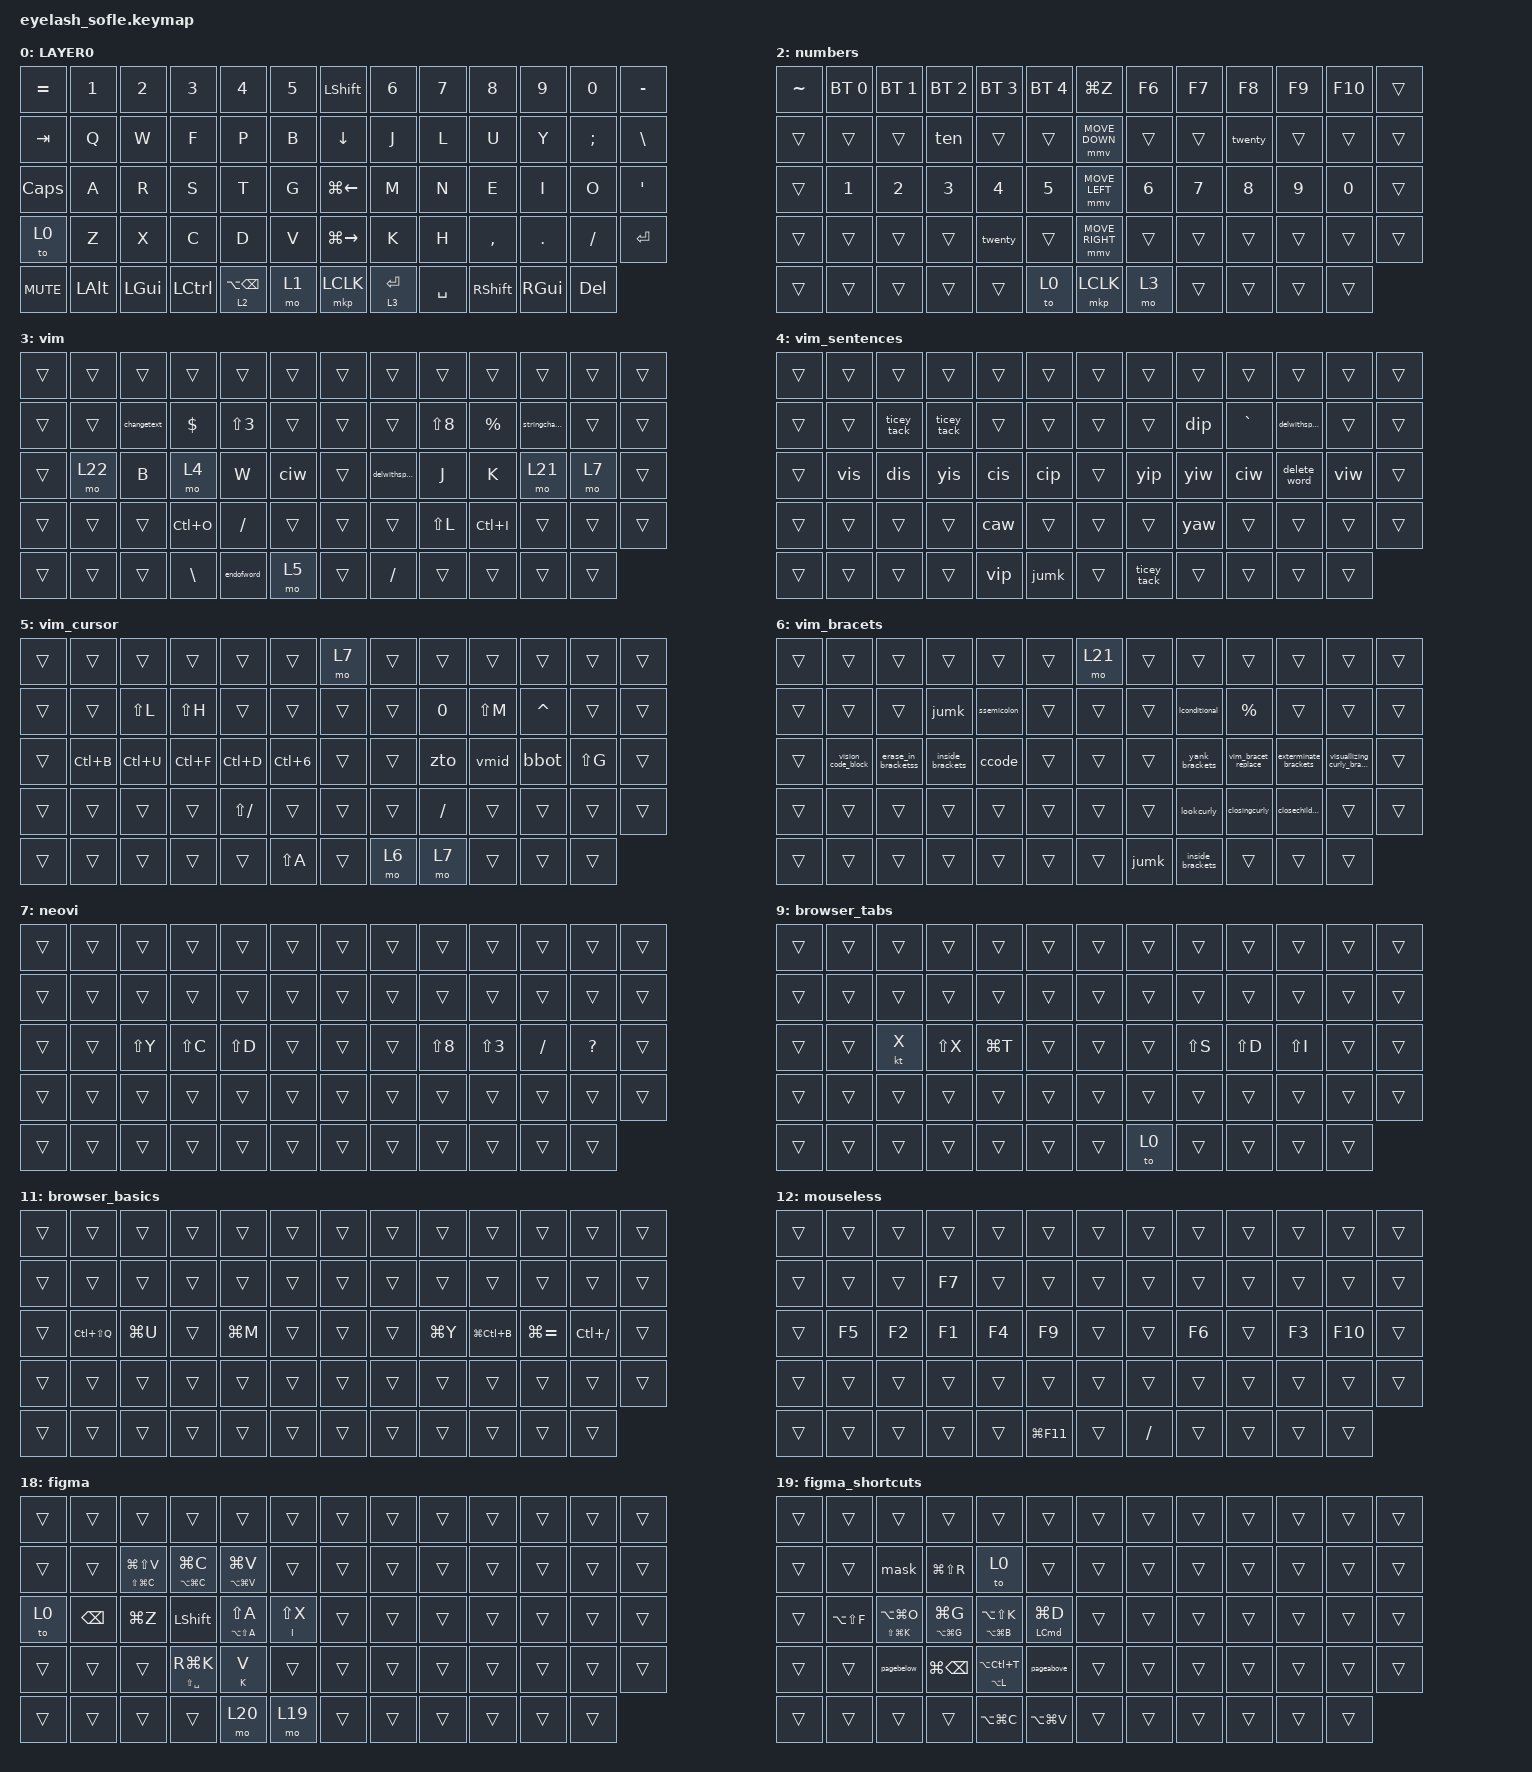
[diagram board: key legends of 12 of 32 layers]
#define ZMK_POINTING_DEFAULT_MOVE_VAL 1200  // 600
#define ZMK_POINTING_DEFAULT_SCRL_VAL 25   // 10

#include <input/processors.dtsi>
#include <zephyr/dt-bindings/input/input-event-codes.h>
#include <behaviors.dtsi>
#include <dt-bindings/zmk/bt.h>
#include <dt-bindings/zmk/keys.h>
#include <dt-bindings/zmk/pointing.h>

&mmv_input_listener { input-processors = <&zip_xy_scaler 2 1>; };

&msc_input_listener { input-processors = <&zip_scroll_scaler 2 1>; };

&msc {
    acceleration-exponent = <1>;      // 0
    time-to-max-speed-ms = <100>;       // 300
    delay-ms = <0>;                   // 0
};

&mmv {
    time-to-max-speed-ms = <500>;
    acceleration-exponent = <1>;
    trigger-period-ms = <16>;
};

/ {
    scroll_encoder: scroll_encoder {
        compatible = "zmk,behavior-sensor-rotate";
        #sensor-binding-cells = <0>;
        bindings = <&msc SCRL_DOWN>, <&msc SCRL_UP>;

        tap-ms = <100>;
    };

    new_behavior: new_behavior {
        compatible = "zmk,behavior-hold-tap";
        label = "NEW_BEHAVIOR";
        bindings = <&mo>, <&kp>;

        #binding-cells = <2>;
        tapping-term-ms = <200>;
        quick-tap-ms = <165>;
        flavor = "tap-preferred";
        hold-trigger-on-release;
    };

    new_behaviorr: new_behaviorr {
        compatible = "zmk,behavior-hold-tap";
        label = "NEW_BEHAVIORR";
        bindings = <&mo>, <&to>;

        #binding-cells = <2>;
        tapping-term-ms = <200>;
        quick-tap-ms = <150>;
        hold-trigger-on-release;
    };

    behaviors {
    };

    combos {
        compatible = "zmk,combos";

        deleteword {
            bindings = <&ciw>;
            key-positions = <30 34>;
        };

        top {
            bindings = <&kp LA(LS(N))>;
            key-positions = <28 29>;
        };

        vimjumps {
            bindings = <&jumk>;
            key-positions = <23 34>;
        };

        searh {
            bindings = <&kp SLASH>;
            key-positions = <27 37>;
        };

        fspace {
            bindings = <&gospace>;
            key-positions = <30 16>;
        };
    };

    macros {
        ciw: ciw {
            compatible = "zmk,behavior-macro";
            #binding-cells = <0>;
            bindings = <&kp C &kp I &kp W>;
            label = "ciw";
        };

        viw: viw {
            compatible = "zmk,behavior-macro";
            #binding-cells = <0>;
            bindings = <&kp V &kp I &kp W>;
            label = "VIW";
        };

        yiw: yiw {
            compatible = "zmk,behavior-macro";
            #binding-cells = <0>;
            bindings = <&kp Y &kp I &kp W>;
            label = "YIW";
        };

        ten: ten {
            compatible = "zmk,behavior-macro";
            #binding-cells = <0>;
            bindings = <&kp NUMBER_1 &kp N0>;
            label = "ten";
        };

        delete_word: delete_word {
            compatible = "zmk,behavior-macro";
            #binding-cells = <0>;
            bindings = <&kp D &kp I &kp W>;
            label = "DELETE_WORD";
        };

        replace_word: replace_word {
            compatible = "zmk,behavior-macro";
            #binding-cells = <0>;
            bindings = <&kp C &kp I &kp LS(W)>;
            label = "REPLACE_WORD";
        };

        visual_w: visual_w {
            compatible = "zmk,behavior-macro";
            #binding-cells = <0>;
            bindings = <&kp V &kp I &kp LS(W)>;
            label = "VISUAL_W";
        };

        copy_word: copy_word {
            compatible = "zmk,behavior-macro";
            #binding-cells = <0>;
            bindings = <&kp Y &kp I &kp LS(W)>;
            label = "COPY_WORD";
        };

        remove_o: remove_o {
            compatible = "zmk,behavior-macro";
            #binding-cells = <0>;
            bindings = <&kp D &kp I &kp LS(W)>;
            label = "REMOVE_O";
        };

        twenty: twenty {
            compatible = "zmk,behavior-macro";
            #binding-cells = <0>;
            bindings = <&kp NUMBER_2 &kp N0>;
            label = "TWENTY";
        };

        vim_bracet_replace: vim_bracet_replace {
            compatible = "zmk,behavior-macro";
            #binding-cells = <0>;
            bindings = <&kp C &kp I &kp B>;
            label = "VIM_BRACET_REPLACE";
        };

        inside_brackets: replace_inside_brackets {
            compatible = "zmk,behavior-macro";
            #binding-cells = <0>;
            bindings = <&kp C &kp I &kp LS(B)>;
            label = "REPLACE_INSIDE_BRACKETS";
        };

        ccode: copy_code {
            compatible = "zmk,behavior-macro";
            #binding-cells = <0>;
            bindings = <&kp Y &kp I &kp B>;
            label = "COPY_CODE";
        };

        yank_brackets: yank_brackets {
            compatible = "zmk,behavior-macro";
            #binding-cells = <0>;
            bindings = <&kp Y &kp I &kp LS(B)>;
            label = "YANK_BRACKETS";
        };

        erase_in_bracketss: erase_in_bracketss {
            compatible = "zmk,behavior-macro";
            #binding-cells = <0>;
            bindings = <&kp D &kp I &kp B>;
            label = "ERASE_IN_BRACKETSS";
        };

        exterminate_brackets: exterminate_brackets {
            compatible = "zmk,behavior-macro";
            #binding-cells = <0>;
            bindings = <&kp D &kp I &kp LS(B)>;
            label = "EXTERMINATE_BRACKETS";
        };

        vision_code_block: vision_code_block {
            compatible = "zmk,behavior-macro";
            #binding-cells = <0>;
            bindings = <&kp V &kp I &kp B>;
            label = "VISION_CODE_BLOCK";
        };

        visuallizing_curly_brackets: visuallizing_curly_brackets {
            compatible = "zmk,behavior-macro";
            #binding-cells = <0>;
            bindings = <&kp V &kp I &kp LS(B)>;
            label = "VISUALLIZING_CURLY_BRACKETS";
        };

        ticey_tack: ticey_tack {
            compatible = "zmk,behavior-macro";
            #binding-cells = <0>;
            bindings = <&kp GRAVE &kp GRAVE>;
            label = "TICEY_TACK";
        };

        zto: zt {
            compatible = "zmk,behavior-macro";
            #binding-cells = <0>;
            bindings = <&kp Z &kp T>;
            label = "ZT";
        };

        vmid: middle {
            compatible = "zmk,behavior-macro";
            #binding-cells = <0>;
            bindings = <&kp Z &kp Z>;
            label = "MIDDLE";
        };

        bbot: bottom {
            compatible = "zmk,behavior-macro";
            #binding-cells = <0>;
            bindings = <&kp Z &kp B>;
            label = "BOTTOM";
        };

        cip: cip {
            compatible = "zmk,behavior-macro";
            #binding-cells = <0>;
            bindings = <&kp C &kp I &kp P>;
            label = "CIP";
        };

        vip: vip {
            compatible = "zmk,behavior-macro";
            #binding-cells = <0>;
            bindings = <&kp V &kp I &kp P>;
            label = "VIP";
        };

        yip: yip {
            compatible = "zmk,behavior-macro";
            #binding-cells = <0>;
            bindings = <&kp Y &kp I &kp P>;
            label = "YIP";
        };

        dip: dip {
            compatible = "zmk,behavior-macro";
            #binding-cells = <0>;
            bindings = <&kp D &kp I &kp P>;
            label = "DIP";
        };

        cis: cis {
            compatible = "zmk,behavior-macro";
            #binding-cells = <0>;
            bindings = <&kp C &kp I &kp S>;
            label = "CIS";
        };

        vis: vis {
            compatible = "zmk,behavior-macro";
            #binding-cells = <0>;
            bindings = <&kp V &kp I &kp S>;
            label = "VIS";
        };

        yis: yis {
            compatible = "zmk,behavior-macro";
            #binding-cells = <0>;
            bindings = <&kp Y &kp I &kp S>;
            label = "YIS";
        };

        dis: dis {
            compatible = "zmk,behavior-macro";
            #binding-cells = <0>;
            bindings = <&kp D &kp I &kp S>;
            label = "DIS";
        };

        caw: caw {
            compatible = "zmk,behavior-macro";
            #binding-cells = <0>;
            bindings = <&kp C &kp A &kp W>;
            label = "CAW";
        };

        yaw: yaw {
            compatible = "zmk,behavior-macro";
            #binding-cells = <0>;
            bindings = <&kp Y &kp A &kp W>;
            label = "YAW";
        };

        endofword: endofword {
            compatible = "zmk,behavior-macro";
            #binding-cells = <0>;
            bindings = <&kp G &kp E>;
            label = "ENDOFWORD";
        };

        jumk: jumpy {
            compatible = "zmk,behavior-macro";
            #binding-cells = <0>;
            bindings = <&kp GRAVE &kp N>;
            label = "JUMPY";
        };

        splitV: splitV {
            compatible = "zmk,behavior-macro";
            #binding-cells = <0>;
            bindings = <&kp SPACE &kp S &kp V>;
            label = "SPLITV";
        };

        horsplit: horsplit {
            compatible = "zmk,behavior-macro";
            #binding-cells = <0>;
            bindings = <&kp SPACE &kp S &kp H>;
            label = "HORSPLIT";
        };

        closesplit: closesplit {
            compatible = "zmk,behavior-macro";
            #binding-cells = <0>;
            bindings = <&kp SPACE &kp S &kp X>;
            label = "CLOSESPLIT";
        };

        changetext: change_text {
            compatible = "zmk,behavior-macro";
            #binding-cells = <0>;
            bindings = <&kp C &kp I &kp DOUBLE_QUOTES>;
            label = "CHANGE_TEXT";
        };

        stringchange: string_change {
            compatible = "zmk,behavior-macro";
            #binding-cells = <0>;
            bindings = <&kp C &kp I &kp SINGLE_QUOTE>;
            label = "STRING_CHANGE";
        };

        fuzzy: fuzzy {
            compatible = "zmk,behavior-macro";
            #binding-cells = <0>;
            bindings = <&kp F &kp Z &kp F>;
            label = "FUZZY";
        };

        aroundpara: around_para {
            compatible = "zmk,behavior-macro";
            #binding-cells = <0>;
            bindings = <&kp D &kp A &kp P>;
            label = "AROUND_PARA";
        };

        gospace: next_space {
            compatible = "zmk,behavior-macro";
            #binding-cells = <0>;
            bindings = <&kp F &kp SPACE>;
            label = "NEXT_SPACE";
        };

        findbra: findbra {
            compatible = "zmk,behavior-macro";
            #binding-cells = <0>;
            bindings = <&kp F &kp LS(N9)>;
            label = "FINDBRA";
        };

        lookcurly: lookcurly {
            compatible = "zmk,behavior-macro";
            #binding-cells = <0>;
            bindings = <&kp F &kp LEFT_BRACE>;
            label = "LOOKCURLY";
        };

        ssemicolon: ssemicolon {
            compatible = "zmk,behavior-macro";
            #binding-cells = <0>;
            bindings = <&kp F &kp SEMICOLON>;
            label = "SSEMICOLON";
        };

        closingcurly: closingcurly {
            compatible = "zmk,behavior-macro";
            #binding-cells = <0>;
            bindings = <&kp F &kp LS(N0)>;
            label = "CLOSINGCURLY";
        };

        lockedbra: lockedbra {
            compatible = "zmk,behavior-macro";
            #binding-cells = <0>;
            bindings = <&kp F &kp RIGHT_BRACE>;
            label = "LOCKEDBRA";
        };

        seechildren: seechildren {
            compatible = "zmk,behavior-macro";
            #binding-cells = <0>;
            bindings = <&kp F &kp LEFT_BRACKET>;
            label = "SEECHILDREN";
        };

        closechildren: closechildren {
            compatible = "zmk,behavior-macro";
            #binding-cells = <0>;
            bindings = <&kp F &kp RIGHT_BRACKET>;
            label = "CLOSECHILDREN";
        };

        lconditional: lconditional {
            compatible = "zmk,behavior-macro";
            #binding-cells = <0>;
            bindings = <&kp F &kp LS(SEMICOLON)>;
            label = "LCONDITIONAL";
        };

        mask: mask {
            compatible = "zmk,behavior-macro";
            #binding-cells = <0>;
            bindings = <&kp CARET &kp LG(M)>;
            label = "MASK";
        };

        Component: Component {
            compatible = "zmk,behavior-macro";
            #binding-cells = <0>;
            bindings = <&kp CARET &kp LA(LG(K))>;
            label = "COMPONENT";
        };

        pagebelow: pagebelow {
            compatible = "zmk,behavior-macro";
            #binding-cells = <0>;
            bindings = <&kp GLOBE &kp DOWN_ARROW>;
            label = "PAGEBELOW";
        };

        pageabove: pageabove {
            compatible = "zmk,behavior-macro";
            #binding-cells = <0>;
            bindings = <&kp GLOBE &kp UP_ARROW>;
            label = "PAGEABOVE";
        };

        mipassword: mipassword {
            compatible = "zmk,behavior-macro";
            #binding-cells = <0>;
            bindings = <&kp M &kp I &kp G &kp B &kp Y &kp T &kp E &kp DLLR &kp PERCENT>;
            label = "MIPASSWORD";
        };

        muxprev: muxprev {
            compatible = "zmk,behavior-macro";
            #binding-cells = <0>;
            bindings = <&kp LC(N) &kp LC(P)>;
            label = "MUXPREV";
        };

        delwithspacedaw: delwithspacedaw {
            compatible = "zmk,behavior-macro";
            #binding-cells = <0>;
            bindings = <&kt D &kp W>;
            label = "DELWITHSPACEDAW";
        };

        winsert: winsert {
            compatible = "zmk,behavior-macro";
            #binding-cells = <0>;
            bindings = <&kp LC(O) &kp W>;
            label = "WINSERT";
        };

        begininsertmode: begininsertmode {
            compatible = "zmk,behavior-macro";
            #binding-cells = <0>;
            bindings = <&kp LC(O) &kp B>;
            label = "BEGININSERTMODE";
        };

        endinertm: doinertm {
            compatible = "zmk,behavior-macro";
            #binding-cells = <0>;
            bindings = <&kp LC(O) &kp RIGHT_ARROW &kp E>;
            label = "DOINERTM";
        };

        var: var {
            compatible = "zmk,behavior-macro";
            #binding-cells = <0>;
            bindings = <&kp DOLLAR &kp V &kp A &kp R>;
            label = "VAR";
        };

        eloquentchain: eloquentchain {
            compatible = "zmk,behavior-macro";
            #binding-cells = <0>;
            bindings = <&kp MINUS &kp GREATER_THAN>;
            label = "ELOQUENTCHAIN";
        };

        phpopening: phpopening {
            compatible = "zmk,behavior-macro";
            #binding-cells = <0>;
            bindings = <&kp LESS_THAN &kp QUESTION &kp P &kp H &kp P &kp QUESTION &kp GREATER_THAN>;
            label = "PHPOPENING";
        };

        array: array {
            compatible = "zmk,behavior-macro";
            #binding-cells = <0>;
            bindings = <&kp EQUAL &kp GREATER_THAN>;
            label = "ARRAY";
        };

        passdata: passdata {
            compatible = "zmk,behavior-macro";
            #binding-cells = <0>;
            bindings = <&none &kp C &kp O &kp M &kp P &kp A &kp C &kp T &kp LPAR &kp SQT &kp V &kp A &kp R &kp SQT &kp RPAR>;
            label = "PASSDATA";
        };

        pssword: pssword {
            compatible = "zmk,behavior-macro";
            #binding-cells = <0>;
            bindings = <&none &kp LS(M) &kp I &kp G &kp B &kp Y &kp T &kp E &kp N1 &kp N9 &kp N9 &kp N6 &kp DLLR>;
            label = "PSSWORD";
        };

        lasteditlo: lasteditlo {
            compatible = "zmk,behavior-macro";
            #binding-cells = <0>;
            bindings = <&kp SINGLE_QUOTE &kp PERIOD>;
            label = "LASTEDITLO";
        };

        lastinertlo: lastinertlo {
            compatible = "zmk,behavior-macro";
            #binding-cells = <0>;
            bindings = <&kp SINGLE_QUOTE &kp CARET>;
            label = "LASTINERTLO";
        };

        lastvimchange: lastvimchange {
            compatible = "zmk,behavior-macro";
            #binding-cells = <0>;
            bindings = <&kp SINGLE_QUOTE &kp LEFT_BRACKET>;
            label = "LASTVIMCHANGE";
        };

        firstvimchange: firstvimchange {
            compatible = "zmk,behavior-macro";
            #binding-cells = <0>;
            bindings = <&kp SQT &kp RIGHT_BRACKET>;
            label = "FIRSTVIMCHANGE";
        };

        entireprojectwordreplace: entireprojectwordreplace {
            compatible = "zmk,behavior-macro";
            #binding-cells = <0>;
            bindings = <&kp COLON &kp C &kp D &kp O &kp SPACE &kp S &kp SLASH>;
            label = "ENTIREPROJECTWORDREPLACE";
        };

        searchpopluateqfixdart: searchpopluateqfix {
            compatible = "zmk,behavior-macro";
            #binding-cells = <0>;
            bindings = <&kp COLON &kp V &kp I &kp M &kp SPACE &kp SLASH &kp BACKSLASH &kp LESS_THAN &kp BACKSLASH &kp GREATER_THAN &kp SLASH &kp G &kp J &kp SPACE &kp ASTERISK &kp ASTERISK &kp SLASH &kp ASTRK &kp PERIOD &kp D &kp A &kp R &kp T &kp LEFT_ARROW &kp LEFT_ARROW &kp LEFT_ARROW &kp LEFT_ARROW &kp LEFT_ARROW &kp LEFT_ARROW &kp LEFT_ARROW &kp LEFT_ARROW &kp LEFT_ARROW &kp LEFT_ARROW &kp LEFT_ARROW &kp LEFT_ARROW &kp LEFT_ARROW &kp LEFT_ARROW &kp LEFT_ARROW>;
            label = "SEARCHPOPLUATEQFIX";
        };

        nexterror: newerror {
            compatible = "zmk,behavior-macro";
            #binding-cells = <0>;
            bindings = <&kp RIGHT_BRACKET &kp E>;
            label = "NEWERROR";
        };

        nextdiagnostic: newdiagnostic {
            compatible = "zmk,behavior-macro";
            #binding-cells = <0>;
            bindings = <&kp RIGHT_BRACKET &kp D>;
            label = "NEWDIAGNOSTIC";
        };

        previousdiagnostic: previousdiagnostic {
            compatible = "zmk,behavior-macro";
            #binding-cells = <0>;
            bindings = <&kp LEFT_BRACKET &kp D>;
            label = "PREVIOUSDIAGNOSTIC";
        };

        previouserror: previouserror {
            compatible = "zmk,behavior-macro";
            #binding-cells = <0>;
            bindings = <&kp LEFT_BRACKET &kp E>;
            label = "PREVIOUSERROR";
        };

        flutterentirewordreplace: flutterentirewordreplace {
            compatible = "zmk,behavior-macro";
            #binding-cells = <0>;
            bindings = <&kp COLON &kp C &kp F &kp D &kp O &kp SPACE &kp PRCNT &kp S &kp FSLH &kp FSLH &kp FSLH &kp G &kp SPACE &kp PIPE &kp SPACE &kp U &kp P &kp D &kp A &kp T &kp E &kp LEFT_ARROW &kp LEFT_ARROW &kp LEFT_ARROW &kp LEFT_ARROW &kp LEFT_ARROW &kp LEFT_ARROW &kp LEFT_ARROW &kp LEFT_ARROW &kp LEFT_ARROW &kp LEFT_ARROW &kp LEFT_ARROW>;
            label = "FLUTTERENTIREWORDREPLACE";
        };

        justreplace: justreplace {
            compatible = "zmk,behavior-macro";
            #binding-cells = <0>;
            bindings = <&kp COLON &kp PRCNT &kp S &kp FSLH &kp FSLH &kp FSLH &kp LEFT_ARROW &kp LEFT_ARROW>;
            label = "JUSTREPLACE";
        };
    };

    keymap {
        compatible = "zmk,keymap";

        kuru {
            bindings = <
&kp EQUAL   &kp N1        &kp N2        &kp N3            &kp N4                         &kp N5    &kp LEFT_SHIFT       &kp N6               &kp N7     &kp N8           &kp N9         &kp N0         &kp MINUS
&kp TAB     &kp Q         &kp W         &kp F             &kp P                          &kp B     &kp DOWN_ARROW       &kp J                &kp L      &kp U            &kp Y          &kp SEMICOLON  &kp BSLH
&kp CAPS    &kp A         &kp R         &kp S             &kp T                          &kp G     &kp LG(LEFT_ARROW)   &kp M                &kp N      &kp E            &kp I          &kp O          &kp APOS
&to 0       &kp Z         &kp X         &kp C             &kp D                          &kp V     &kp LG(RIGHT_ARROW)  &kp K                &kp H      &kp COMMA        &kp DOT        &kp FSLH       &kp ENTER
&kp C_MUTE  &kp LEFT_ALT  &kp LEFT_GUI  &kp LEFT_CONTROL  &new_behavior 2 LA(BACKSPACE)  &mo 1     &mkp LCLK            &new_behavior 3 RET  &kp SPACE  &kp RIGHT_SHIFT  &kp RIGHT_GUI  &kp DELETE
            >;

            sensor-bindings = <&inc_dec_kp C_VOLUME_UP C_VOL_DN>;
            display-name = "LAYER0";
        };

        all {
            bindings = <
&sys_reset    &bt BT_CLR_ALL  &bt BT_CLR  &bt BT_NXT  &bt BT_PRV  &bt BT_SEL 4    &kp LG(BACKSPACE)  &kp F6             &kp F7                 &kp F8         &kp F9            &kp F10  &sys_reset
&bt BT_SEL 1  &none           &kp LG(Y)   &kp LG(W)   &to 18      &trans          &mmv MOVE_DOWN     &kp DOUBLE_QUOTES  &kp LC(LA(LG(SLASH)))  &mo 8          &kp SINGLE_QUOTE  &trans   &trans
&sys_reset    &mo 23          &mo 26      &mo 6       &mo 13      &kp F8          &mmv MOVE_LEFT     &kp LC(LA(LG(F)))  &kp TAB                &kp LC(W)      &kp ESCAPE        &mo 30   &kp Z
&bt BT_SEL 0  &trans          &kp LG(X)   &kp LG(C)   &kp LG(V)   &trans          &mmv MOVE_RIGHT    &trans             &findbra               &closingcurly  &seechildren      &trans   &pssword
&trans        &trans          &trans      &trans      &trans      &trans          &mkp LCLK          &kp LC(S)          &mo 17                 &kp LG(Z)      &mipassword       &trans
            >;

            display-name = "layer1";
            sensor-bindings = <&scroll_encoder>;
        };

        numbers {
            bindings = <
&kp TILDE  &bt BT_SEL 0  &bt BT_SEL 1  &bt BT_SEL 2  &bt BT_SEL 3  &bt BT_SEL 4    &kp LG(Z)        &kp F6        &kp F7  &kp F8   &kp F9  &kp F10  &trans
&trans     &trans        &trans        &ten          &trans        &trans          &mmv MOVE_DOWN   &trans        &trans  &twenty  &trans  &trans   &trans
&trans     &kp NUMBER_1  &kp NUMBER_2  &kp NUMBER_3  &kp NUMBER_4  &kp N5          &mmv MOVE_LEFT   &kp NUMBER_6  &kp N7  &kp N8   &kp N9  &kp N0   &trans
&trans     &trans        &trans        &trans        &twenty       &trans          &mmv MOVE_RIGHT  &trans        &trans  &trans   &trans  &trans   &trans
&trans     &trans        &trans        &trans        &trans        &to 0           &mkp LCLK        &mo 3         &trans  &trans   &trans  &trans
            >;

            sensor-bindings = <&scroll_encoder>;
        };

        vim {
            bindings = <
&trans  &trans  &trans       &trans         &trans            &trans    &trans  &trans            &trans      &trans       &trans         &trans  &trans
&trans  &trans  &changetext  &kp DOLLAR     &kp LS(NUMBER_3)  &trans    &trans  &trans            &kp LS(N8)  &kp PERCENT  &stringchange  &trans  &trans
&trans  &mo 22  &kp B        &mo 4          &kp W             &ciw      &trans  &delwithspacedaw  &kp J       &kp K        &mo 21         &mo 7   &trans
&trans  &trans  &trans       &kp LC(O)      &kp SLASH         &trans    &trans  &trans            &kp LS(L)   &kp LC(I)    &trans         &trans  &trans
&trans  &trans  &trans       &kp BACKSLASH  &endofword        &mo 5     &trans  &kp SLASH         &trans      &trans       &trans         &trans
            >;

            sensor-bindings = <&inc_dec_kp PLUS KP_SUBTRACT>;
        };

        vim_sentences {
            bindings = <
&trans  &trans  &trans       &trans       &trans  &trans    &trans  &trans       &trans  &trans     &trans            &trans  &trans
&trans  &trans  &ticey_tack  &ticey_tack  &trans  &trans    &trans  &trans       &dip    &kp GRAVE  &delwithspacedaw  &trans  &trans
&trans  &vis    &dis         &yis         &cis    &cip      &trans  &yip         &yiw    &ciw       &delete_word      &viw    &trans
&trans  &trans  &trans       &trans       &caw    &trans    &trans  &trans       &yaw    &trans     &trans            &trans  &trans
&trans  &trans  &trans       &trans       &vip    &jumk     &trans  &ticey_tack  &trans  &trans     &trans            &trans
            >;
        };

        vim_cursor {
            bindings = <
&trans  &trans     &trans     &trans     &trans         &trans              &mo 7   &trans  &trans     &trans     &trans     &trans     &trans
&trans  &trans     &kp LS(L)  &kp LS(H)  &trans         &trans              &trans  &trans  &kp N0     &kp LS(M)  &kp CARET  &trans     &trans
&trans  &kp LC(B)  &kp LC(U)  &kp LC(F)  &kp LC(D)      &kp LC(NUMBER_6)    &trans  &trans  &zto       &vmid      &bbot      &kp LS(G)  &trans
&trans  &trans     &trans     &trans     &kp LS(SLASH)  &trans              &trans  &trans  &kp SLASH  &trans     &trans     &trans     &trans
&trans  &trans     &trans     &trans     &trans         &kp LS(A)           &trans  &mo 6   &mo 7      &trans     &trans     &trans
            >;
        };

        vim_bracets {
            bindings = <
&trans  &trans              &trans               &trans            &trans       &trans    &mo 21  &trans  &trans            &trans               &trans                 &trans                        &trans
&trans  &trans              &trans               &jumk             &ssemicolon  &trans    &trans  &trans  &lconditional     &kp PERCENT          &trans                 &trans                        &trans
&trans  &vision_code_block  &erase_in_bracketss  &inside_brackets  &ccode       &trans    &trans  &trans  &yank_brackets    &vim_bracet_replace  &exterminate_brackets  &visuallizing_curly_brackets  &trans
&trans  &trans              &trans               &trans            &trans       &trans    &trans  &trans  &lookcurly        &closingcurly        &closechildren         &trans                        &trans
&trans  &trans              &trans               &trans            &trans       &trans    &trans  &jumk   &inside_brackets  &trans               &trans                 &trans
            >;
        };

        neovi {
            bindings = <
&trans  &trans  &trans     &trans     &trans     &trans    &trans  &trans  &trans      &trans            &trans     &trans        &trans
&trans  &trans  &trans     &trans     &trans     &trans    &trans  &trans  &trans      &trans            &trans     &trans        &trans
&trans  &trans  &kp LS(Y)  &kp LS(C)  &kp LS(D)  &trans    &trans  &trans  &kp LS(N8)  &kp LS(NUMBER_3)  &kp SLASH  &kp QUESTION  &trans
&trans  &trans  &trans     &trans     &trans     &trans    &trans  &trans  &trans      &trans            &trans     &trans        &trans
&trans  &trans  &trans     &trans     &trans     &trans    &trans  &trans  &trans      &trans            &trans     &trans
            >;
        };

        browser {
            bindings = <
&trans  &trans             &trans  &trans             &trans             &trans               &mo 12  &trans  &trans     &trans  &trans     &trans  &trans
&trans  &trans             &trans  &kp LG(W)          &trans             &trans               &trans  &trans  &trans     &trans  &kp LG(T)  &trans  &trans
&trans  &kp LC(LA(LS(F)))  &trans  &kp LC(LA(LS(B)))  &kp LC(LA(LS(P)))  &kp LS(LA(LC(W)))    &trans  &trans  &kp LS(E)  &trans  &kp LS(R)  &mo 11  &trans
&trans  &trans             &trans  &trans             &trans             &trans               &trans  &trans  &trans     &trans  &trans     &trans  &trans
&trans  &trans             &trans  &trans             &trans             &trans               &trans  &mo 12  &trans     &trans  &trans     &trans
            >;
        };

        browser_tabs {
            bindings = <
&trans  &trans  &trans  &trans     &trans     &trans    &trans  &trans  &trans     &trans     &trans     &trans  &trans
&trans  &trans  &trans  &trans     &trans     &trans    &trans  &trans  &trans     &trans     &trans     &trans  &trans
&trans  &trans  &kt X   &kp LS(X)  &kp LG(T)  &trans    &trans  &trans  &kp LS(S)  &kp LS(D)  &kp LS(I)  &trans  &trans
&trans  &trans  &trans  &trans     &trans     &trans    &trans  &trans  &trans     &trans     &trans     &trans  &trans
&trans  &trans  &trans  &trans     &trans     &trans    &trans  &to 0   &trans     &trans     &trans     &trans
            >;
        };

        browser_shortcuts {
            bindings = <
&trans  &trans  &trans      &trans         &trans        &trans    &trans  &trans  &trans         &trans     &trans                 &trans                         &trans
&trans  &trans  &trans      &trans         &trans        &trans    &trans  &trans  &trans         &trans     &trans                 &trans                         &trans
&trans  &trans  &kp LG(N0)  &kp LG(MINUS)  &kp LG(PLUS)  &trans    &trans  &trans  &kp LG(LS(P))  &kp LC(P)  &kp LG(LA(LC(LS(X))))  &kp LS(LA(LC(LG(SEMICOLON))))  &trans
&trans  &trans  &trans      &trans         &trans        &trans    &trans  &trans  &trans         &trans     &trans                 &trans                         &trans
&trans  &trans  &trans      &trans         &trans        &trans    &trans  &trans  &trans         &trans     &trans                 &trans
            >;
        };

        browser_basics {
            bindings = <
&trans  &trans         &trans     &trans  &trans     &trans    &trans  &trans  &trans     &trans         &trans         &trans         &trans
&trans  &trans         &trans     &trans  &trans     &trans    &trans  &trans  &trans     &trans         &trans         &trans         &trans
&trans  &kp LC(LS(Q))  &kp LG(U)  &trans  &kp LG(M)  &trans    &trans  &trans  &kp LG(Y)  &kp LG(LC(B))  &kp LG(EQUAL)  &kp LC(SLASH)  &trans
&trans  &trans         &trans     &trans  &trans     &trans    &trans  &trans  &trans     &trans         &trans         &trans         &trans
&trans  &trans         &trans     &trans  &trans     &trans    &trans  &trans  &trans     &trans         &trans         &trans
            >;
        };

        mouseless {
            bindings = <
&trans  &trans  &trans  &trans  &trans  &trans         &trans  &trans     &trans  &trans  &trans  &trans   &trans
&trans  &trans  &trans  &kp F7  &trans  &trans         &trans  &trans     &trans  &trans  &trans  &trans   &trans
&trans  &kp F5  &kp F2  &kp F1  &kp F4  &kp F9         &trans  &trans     &kp F6  &trans  &kp F3  &kp F10  &trans
&trans  &trans  &trans  &trans  &trans  &trans         &trans  &trans     &trans  &trans  &trans  &trans   &trans
&trans  &trans  &trans  &trans  &trans  &kp LG(F11)    &trans  &kp SLASH  &trans  &trans  &trans  &trans
            >;
        };

        raycast {
            bindings = <
&trans  &trans              &trans             &trans             &trans  &trans    &mo 15  &trans                 &trans             &trans                  &trans                 &trans                 &trans
&trans  &trans              &kp LS(LG(COMMA))  &kp LS(LA(LC(G)))  &trans  &trans    &trans  &kp LS(LG(C))          &kp LG(Y)          &kp LS(LA(LG(PERIOD)))  &kp LG(PERIOD)         &trans                 &trans
&trans  &kp LG(LS(PERIOD))  &mo 14             &mo 17             &trans  &trans    &trans  &kp LG(LA(LC(LS(Y))))  &kp LS(LC(COMMA))  &kp LS(LC(LG(LA(U))))   &kp LS(LG(LA(LC(I))))  &kp LC(LA(LS(X)))      &trans
&trans  &trans              &kp LC(X)          &kp LS(LG(R))      &trans  &trans    &trans  &kp LG(I)              &kp RG(K)          &kp LG(O)               &kp LG(RETURN)         &kp LS(LC(LA(SLASH)))  &trans
&trans  &trans              &trans             &trans             &trans  &trans    &trans  &kp LC(LA(Y))          &kp LS(LG(L))      &kp LC(LS(Q))           &trans                 &trans
            >;
        };

        raycast_apps {
            bindings = <
&trans  &trans  &trans  &trans  &trans  &trans    &trans  &trans         &trans             &trans                 &trans                 &trans                 &trans
&trans  &trans  &trans  &trans  &trans  &trans    &trans  &trans         &trans             &kp LG(LC(LA(LS(D))))  &trans                 &trans                 &trans
&trans  &trans  &trans  &trans  &trans  &trans    &trans  &kp LS(LG(Z))  &kp LA(LS(LG(G)))  &kp LG(K)              &kp LS(LA(LG(LC(L))))  &kp LG(LA(LC(LS(K))))  &trans
&trans  &trans  &trans  &trans  &trans  &trans    &trans  &trans         &trans             &trans                 &trans                 &trans                 &trans
&trans  &trans  &trans  &trans  &trans  &mo 15    &trans  &kp LC(LS(Q))  &trans             &trans                 &trans                 &trans
            >;
        };

        raycast_apps_two {
            bindings = <
&trans  &trans  &trans  &trans  &trans  &trans    &trans  &trans                 &trans                 &trans                 &trans                 &trans  &trans
&trans  &trans  &trans  &trans  &trans  &trans    &trans  &trans                 &trans                 &kp LC(LG(LA(LS(H))))  &trans                 &trans  &trans
&trans  &trans  &trans  &mo 16  &trans  &trans    &trans  &trans                 &kp LS(LA(LC(LG(O))))  &kp LS(LG(Z))          &kp LS(LA(LC(LG(W))))  &trans  &trans
&trans  &trans  &trans  &trans  &trans  &trans    &trans  &trans                 &trans                 &trans                 &trans                 &trans  &trans
&trans  &trans  &trans  &trans  &trans  &trans    &trans  &kp LG(LC(LS(LA(B))))  &kp LS(LA(LC(LG(M))))  &trans                 &trans                 &trans
            >;
        };

        raycast_app_three {
            bindings = <
&trans  &trans  &trans  &trans  &trans  &trans    &trans  &trans             &trans         &trans                 &trans                 &trans  &trans
&trans  &trans  &trans  &trans  &trans  &trans    &trans  &trans             &trans         &trans                 &trans                 &trans  &trans
&trans  &trans  &trans  &trans  &trans  &trans    &trans  &trans             &kp LA(LC(Y))  &kp LS(LA(LC(LG(A))))  &kp LG(LC(LA(LS(P))))  &trans  &trans
&trans  &trans  &trans  &trans  &trans  &trans    &trans  &trans             &trans         &trans                 &trans                 &trans  &trans
&trans  &trans  &trans  &trans  &trans  &trans    &trans  &kp LS(LG(LA(B)))  &trans         &trans                 &trans                 &trans
            >;
        };

        tmux_ghostty {
            bindings = <
&trans  &trans           &trans          &trans                     &trans                   &trans    &trans  &trans  &trans                     &trans     &trans                 &trans                         &trans
&trans  &trans           &trans          &entireprojectwordreplace  &trans                   &trans    &trans  &trans  &trans                     &kp LG(A)  &justreplace           &trans                         &trans
&trans  &firstvimchange  &lastvimchange  &lastinertlo               &lasteditlo              &trans    &trans  &trans  &kp LC(LS(R))              &kp LC(N)  &kp LG(LC(LA(LS(Z))))  &kp LG(LC(LA(LS(SEMICOLON))))  &trans
&trans  &trans           &trans          &trans                     &searchpopluateqfixdart  &trans    &trans  &trans  &flutterentirewordreplace  &trans     &trans                 &trans                         &trans
&trans  &trans           &trans          &trans                     &trans                   &trans    &trans  &trans  &trans                     &trans     &trans                 &trans
            >;
        };

        figma {
            bindings = <
&trans  &trans         &trans                   &trans               &trans               &trans         &trans  &trans  &trans  &trans  &trans  &trans  &trans
&trans  &trans         &mt LS(LG(C)) LG(LS(V))  &mt LA(LG(C)) LG(C)  &mt LA(LG(V)) LG(V)  &trans         &trans  &trans  &trans  &trans  &trans  &trans  &trans
&to 0   &kp BACKSPACE  &kp LG(Z)                &kp LEFT_SHIFT       &mt LA(LS(A)) LS(A)  &mt I LS(X)    &trans  &trans  &trans  &trans  &trans  &trans  &trans
&trans  &trans         &trans                   &mt LS(SPACE) RG(K)  &mt K V              &trans         &trans  &trans  &trans  &trans  &trans  &trans  &trans
&trans  &trans         &trans                   &trans               &mo 20               &mo 19         &trans  &trans  &trans  &trans  &trans  &trans
            >;

            sensor-bindings = <&inc_dec_kp C_AC_ZOOM_IN C_AC_ZOOM_OUT>;
        };

        figma_shortcuts {
            bindings = <
&trans  &trans         &trans                   &trans               &trans                   &trans                    &trans  &trans  &trans  &trans  &trans  &trans  &trans
&trans  &trans         &mask                    &kp LG(LS(R))        &to 0                    &trans                    &trans  &trans  &trans  &trans  &trans  &trans  &trans
&trans  &kp LA(LS(F))  &mt LS(LG(K)) LA(LG(O))  &mt LA(LG(G)) LG(G)  &mt LA(LG(B)) LA(LS(K))  &mt LEFT_COMMAND LG(D)    &trans  &trans  &trans  &trans  &trans  &trans  &trans
&trans  &trans         &pagebelow               &kp LG(BACKSPACE)    &mt LA(L) LA(LC(T))      &pageabove                &trans  &trans  &trans  &trans  &trans  &trans  &trans
&trans  &trans         &trans                   &trans               &kp LA(LG(C))            &kp LA(LG(V))             &trans  &trans  &trans  &trans  &trans  &trans
            >;
        };

        figma_aliases {
            bindings = <
&trans  &trans           &trans                    &trans                                      &trans                                      &trans                    &trans  &trans  &trans  &trans  &trans  &trans  &trans
&trans  &trans           &kp LS(N)                 &mt LS(SLASH) LA(SLASH)                     &mt LS(N) N                                 &trans                    &trans  &trans  &trans  &trans  &trans  &trans  &trans
&trans  &mt F LA(LG(L))  &mt R LA(LG(T))           &mt O LG(C_AC_NEXT_KEYBOARD_LAYOUT_SELECT)  &mt T LG(C_AC_NEXT_KEYBOARD_LAYOUT_SELECT)  &Component                &trans  &trans  &trans  &trans  &trans  &trans  &trans
&trans  &trans           &mt LA(A) LS(LEFT_ARROW)  &mt LA(D) LS(RIGHT_ARROW)                   &mt LA(S) LS(DOWN_ARROW)                    &mt LA(W) LS(UP_ARROW)    &trans  &trans  &trans  &trans  &trans  &trans  &trans
&trans  &trans           &trans                    &trans                                      &kp LG(NUMBER_1)                            &kp LG(NUMBER_2)          &trans  &trans  &trans  &trans  &trans  &trans
            >;
        };

        vimuium {
            bindings = <
&trans  &trans               &trans           &trans          &trans             &trans      &trans  &trans     &trans     &trans            &trans       &trans  &trans
&trans  &trans               &trans           &kp Q           &trans             &trans      &trans  &trans     &trans     &kp LS(NUMBER_2)  &trans       &trans  &trans
&trans  &previousdiagnostic  &nextdiagnostic  &previouserror  &nexterror         &trans      &trans  &trans     &kp LC(N)  &kp LC(P)         &aroundpara  &fuzzy  &trans
&trans  &trans               &trans           &trans          &trans             &trans      &trans  &trans     &trans     &trans            &trans       &trans  &trans
&trans  &trans               &trans           &trans          &kp LG(BACKSPACE)  &muxprev    &trans  &kp LC(O)  &trans     &trans            &trans       &trans
            >;
        };

        fucs {
            bindings = <
&trans  &trans        &trans       &trans   &trans     &trans    &trans  &trans  &trans     &trans     &trans     &trans     &trans
&trans  &trans        &trans       &trans   &trans     &trans    &trans  &trans  &trans     &trans     &trans     &trans     &trans
&trans  &kp NUMBER_6  &closesplit  &splitV  &horsplit  &trans    &trans  &trans  &kp LC(H)  &kp LC(L)  &kp LC(J)  &kp LC(K)  &trans
&trans  &trans        &trans       &trans   &trans     &trans    &trans  &trans  &trans     &trans     &trans     &trans     &trans
&trans  &trans        &trans       &trans   &trans     &trans    &trans  &trans  &trans     &trans     &trans     &trans
            >;
        };

        workspaces {
            bindings = <
&trans  &trans  &trans         &trans     &trans             &trans    &trans  &trans  &trans             &trans             &trans             &trans             &trans
&trans  &trans  &trans         &kp LC(H)  &trans             &trans    &trans  &trans  &trans             &kp LC(L)          &kp LG(LA(LS(U)))  &trans             &trans
&trans  &trans  &kp LA(LG(E))  &mo 24     &kp LG(LA(LS(B)))  &trans    &trans  &trans  &kp LG(LA(LS(S)))  &kp LG(LA(LS(D)))  &kp LG(LA(LS(F)))  &kp LG(LS(LA(G)))  &trans
&trans  &trans  &trans         &trans     &kp LC(J)          &none     &trans  &trans  &kp LC(K)          &trans             &trans             &trans             &trans
&trans  &trans  &trans         &trans     &trans             &trans    &trans  &mo 25  &trans             &trans             &trans             &trans
            >;
        };

        workspace_layouts {
            bindings = <
&trans  &trans         &trans  &trans  &trans          &trans    &kp LG(MINUS)  &trans             &trans         &trans         &trans         &trans         &trans
&trans  &trans         &trans  &trans  &trans          &trans    &trans         &trans             &trans         &trans         &trans         &trans         &trans
&trans  &kp LG(SLASH)  &trans  &trans  &kp LG(PERIOD)  &trans    &trans         &trans             &kp LG(LS(H))  &kp LG(LS(J))  &kp LG(LS(K))  &kp LG(LS(L))  &trans
&trans  &trans         &trans  &trans  &trans          &trans    &trans         &trans             &trans         &trans         &trans         &trans         &trans
&trans  &trans         &trans  &trans  &trans          &trans    &trans         &kp LS(LG(EQUAL))  &trans         &trans         &trans         &trans
            >;
        };

        wordspace_focus {
            bindings = <
&trans  &trans     &trans  &trans  &trans         &trans    &trans  &trans  &trans     &trans     &trans     &trans     &trans
&trans  &trans     &trans  &trans  &trans         &trans    &trans  &trans  &trans     &trans     &trans     &trans     &trans
&trans  &kp LG(E)  &trans  &trans  &kp LG(LS(A))  &trans    &trans  &trans  &kp LG(H)  &kp LG(J)  &kp LG(K)  &kp LG(L)  &trans
&trans  &trans     &trans  &trans  &trans         &trans    &trans  &trans  &trans     &trans     &trans     &trans     &trans
&trans  &trans     &trans  &trans  &trans         &trans    &trans  &trans  &trans     &trans     &trans     &trans
            >;
        };

        arrow_movements {
            bindings = <
&trans  &trans  &trans  &trans  &trans  &trans    &kp LA(LS(UP_ARROW))     &trans  &trans          &trans        &trans          &trans           &trans
&trans  &trans  &trans  &trans  &trans  &trans    &kp LA(LS(DOWN_ARROW))   &trans  &trans          &trans        &trans          &trans           &trans
&trans  &mo 28  &trans  &mo 27  &mo 29  &trans    &kp LA(LS(LEFT_ARROW))   &trans  &kp DOWN_ARROW  &kp UP_ARROW  &kp LEFT_ARROW  &kp RIGHT_ARROW  &trans
&trans  &trans  &trans  &trans  &trans  &trans    &kp LA(LS(RIGHT_ARROW))  &trans  &trans          &trans        &trans          &trans           &trans
&trans  &trans  &trans  &trans  &trans  &trans    &trans                   &trans  &trans          &trans        &trans          &trans
            >;
        };

        best_move {
            bindings = <
&trans  &trans  &trans  &trans  &trans  &trans    &trans  &trans  &trans              &trans               &trans              &trans            &trans
&trans  &trans  &trans  &trans  &trans  &trans    &trans  &trans  &trans              &trans               &trans              &trans            &trans
&trans  &trans  &trans  &trans  &trans  &trans    &trans  &trans  &kp LA(LEFT_ARROW)  &kp LA(RIGHT_ARROW)  &kp LA(DOWN_ARROW)  &kp LA(UP_ARROW)  &trans
&trans  &trans  &trans  &trans  &trans  &trans    &trans  &trans  &trans              &trans               &trans              &trans            &trans
&trans  &trans  &trans  &trans  &trans  &trans    &trans  &trans  &trans              &trans               &trans              &trans
            >;
        };

        gar {
            bindings = <
&trans  &trans  &trans  &trans  &trans  &trans    &trans  &trans  &trans              &trans               &trans              &trans            &trans
&trans  &trans  &trans  &trans  &trans  &trans    &trans  &trans  &trans              &trans               &trans              &trans            &trans
&trans  &trans  &trans  &trans  &trans  &trans    &trans  &trans  &kp LG(LEFT_ARROW)  &kp LG(RIGHT_ARROW)  &kp LG(DOWN_ARROW)  &kp LG(UP_ARROW)  &trans
&trans  &trans  &trans  &trans  &trans  &trans    &trans  &trans  &trans              &trans               &trans              &trans            &trans
&trans  &trans  &trans  &trans  &trans  &trans    &trans  &trans  &trans              &trans               &trans              &trans
            >;
        };

        fastestt {
            bindings = <
&trans  &trans  &trans  &trans  &trans  &trans    &trans  &trans  &trans            &trans    &trans      &trans     &trans
&trans  &trans  &trans  &trans  &trans  &trans    &trans  &trans  &trans            &trans    &trans      &trans     &trans
&trans  &trans  &trans  &trans  &trans  &trans    &trans  &trans  &begininsertmode  &winsert  &endinertm  &kp LC(O)  &trans
&trans  &trans  &trans  &trans  &trans  &trans    &trans  &trans  &trans            &trans    &trans      &trans     &trans
&trans  &trans  &trans  &trans  &trans  &trans    &trans  &trans  &trans            &trans    &trans      &trans
            >;
        };

        xeue {
            bindings = <
&trans  &trans            &trans             &trans          &trans             &trans       &trans  &trans     &trans      &trans      &trans         &trans  &trans
&trans  &trans            &kp AMPERSAND      &kp UNDER       &kp HASH           &trans       &trans  &trans     &kp DOLLAR  &kp MINUS   &kp ASTRK      &trans  &trans
&trans  &kp LEFT_BRACKET  &kp RIGHT_BRACKET  &kp LEFT_BRACE  &kp RIGHT_BRACE    &kp TILDE    &trans  &kp EQUAL  &kp LS(N9)  &kp LS(N0)  &kp SEMICOLON  &trans  &trans
&trans  &trans            &trans             &trans          &kp LS(SEMICOLON)  &trans       &trans  &trans     &kp AT      &trans      &trans         &trans  &trans
&trans  &trans            &trans             &trans          &trans             &trans       &trans  &mo 31     &trans      &trans      &trans         &trans
            >;
        };

        rogra {
            bindings = <
&trans  &trans    &trans     &trans     &trans          &trans    &trans  &trans  &trans         &trans        &trans            &trans        &trans
&trans  &trans    &kp PIPE   &kp EQUAL  &passdata       &trans    &trans  &trans  &phpopening    &kp MINUS     &var              &trans        &trans
&trans  &kp EXCL  &kp SLASH  &kp PLUS   &kp BACKSLASH   &trans    &trans  &trans  &kp LESS_THAN  &kp QUESTION  &kp GREATER_THAN  &kp QUESTION  &trans
&trans  &trans    &trans     &trans     &eloquentchain  &trans    &trans  &trans  &array         &trans        &trans            &trans        &trans
&trans  &trans    &trans     &trans     &trans          &trans    &trans  &trans  &trans         &trans        &trans            &trans
            >;
        };
    };
};
